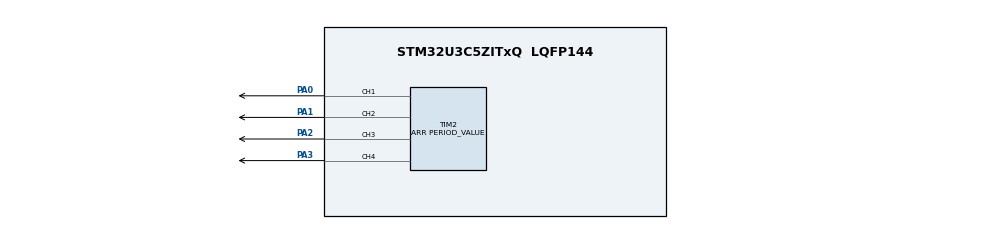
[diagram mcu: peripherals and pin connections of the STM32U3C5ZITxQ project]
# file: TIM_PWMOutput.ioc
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CORTEX_M33_NS.userName=CORTEX_M33
Mcu.Family=STM32U3
Mcu.Name=STM32U3C5ZITxQ
Mcu.Package=LQFP144
NVIC.PriorityGroup=NVIC_PRIORITYGROUP_4
PA0.GPIO_PuPd=GPIO_PULLUP
PA0.GPIO_Speed=GPIO_SPEED_FREQ_VERY_HIGH
PA0.Signal=S_TIM2_CH1
PA1.GPIO_PuPd=GPIO_PULLUP
PA1.GPIO_Speed=GPIO_SPEED_FREQ_VERY_HIGH
PA1.Signal=S_TIM2_CH2
PA2.GPIO_PuPd=GPIO_PULLUP
PA2.GPIO_Speed=GPIO_SPEED_FREQ_VERY_HIGH
PA2.Signal=S_TIM2_CH3
PA3.GPIO_PuPd=GPIO_PULLUP
PA3.GPIO_Speed=GPIO_SPEED_FREQ_VERY_HIGH
PA3.Signal=S_TIM2_CH4
ProjectManager.HeapSize=0x200
ProjectManager.StackSize=0x400
ProjectManager.TargetToolchain=EWARM V9.20
RCC.ADCFreq_Value=96000000
RCC.AHBFreq_Value=96000000
RCC.APB1Freq_Value=96000000
RCC.APB1TimFreq_Value=96000000
RCC.APB2Freq_Value=96000000
RCC.APB2TimFreq_Value=96000000
RCC.APB3Freq_Value=96000000
RCC.CortexFreq_Value=12000000
RCC.HCLKFreq_Value=96000000
RCC.HSE_VALUE=16000000
RCC.HSI48_VALUE=48000000
RCC.HSI_VALUE=16000000
RCC.LSE_VALUE=32768
RCC.LSIDIV_VALUE=32000
RCC.MSISDIV=RCC_MSI_DIV1
RCC.MSI_VALUE=96000000
RCC.PWR_Regulator_Voltage_Scale=PWR_REGULATOR_VOLTAGE_SCALE1
RCC.SYSCLKFreq_VALUE=96000000
RCC.USBFreq_Value=96000000
SH.S_TIM2_CH1.0=TIM2_CH1,PWM Generation1 CH1
SH.S_TIM2_CH2.0=TIM2_CH2,PWM Generation2 CH2
SH.S_TIM2_CH3.0=TIM2_CH3,PWM Generation3 CH3
SH.S_TIM2_CH4.0=TIM2_CH4,PWM Generation4 CH4
TIM2.AutoReloadPreload=TIM_AUTORELOAD_PRELOAD_DISABLE
TIM2.Channel-PWM\ Generation1\ CH1=TIM_CHANNEL_1
TIM2.Channel-PWM\ Generation2\ CH2=TIM_CHANNEL_2
TIM2.Channel-PWM\ Generation3\ CH3=TIM_CHANNEL_3
TIM2.Channel-PWM\ Generation4\ CH4=TIM_CHANNEL_4
TIM2.ClearInputSource=TIM_CLEARINPUTSOURCE_NONE
TIM2.ClockDivision=TIM_CLOCKDIVISION_DIV1
TIM2.CounterMode=TIM_COUNTERMODE_UP
TIM2.OC1Preload_PWM=ENABLE
TIM2.OC2Preload_PWM=ENABLE
TIM2.OC3Preload_PWM=ENABLE
TIM2.OC4Preload_PWM=ENABLE
TIM2.OCFastMode_PWM-PWM\ Generation1\ CH1=TIM_OCFAST_DISABLE
TIM2.OCFastMode_PWM-PWM\ Generation2\ CH2=TIM_OCFAST_DISABLE
TIM2.OCFastMode_PWM-PWM\ Generation3\ CH3=TIM_OCFAST_DISABLE
TIM2.OCFastMode_PWM-PWM\ Generation4\ CH4=TIM_OCFAST_DISABLE
TIM2.OCMode_PWM-PWM\ Generation1\ CH1=TIM_OCMODE_PWM1
TIM2.OCMode_PWM-PWM\ Generation2\ CH2=TIM_OCMODE_PWM1
TIM2.OCMode_PWM-PWM\ Generation3\ CH3=TIM_OCMODE_PWM1
TIM2.OCMode_PWM-PWM\ Generation4\ CH4=TIM_OCMODE_PWM1
TIM2.OCPolarity_1=TIM_OCPOLARITY_HIGH
TIM2.OCPolarity_2=TIM_OCPOLARITY_HIGH
TIM2.OCPolarity_3=TIM_OCPOLARITY_HIGH
TIM2.OCPolarity_4=TIM_OCPOLARITY_HIGH
TIM2.Period=PERIOD_VALUE
TIM2.Prescaler=PRESCALER_VALUE
TIM2.PulseNoDither_1=PULSE1_VALUE
TIM2.PulseNoDither_2=PULSE2_VALUE
TIM2.PulseNoDither_3=PULSE3_VALUE
TIM2.PulseNoDither_4=PULSE4_VALUE
TIM2.TIM_MasterOutputTrigger=TIM_TRGO_RESET
TIM2.TIM_MasterSlaveMode=TIM_MASTERSLAVEMODE_DISABLE
VP_ICACHE_VS_ICACHE.Mode=DirectMappedCache
VP_PWR_VS_DBSignals.Mode=DisableDeadBatterySignals
VP_PWR_VS_LPOM.Mode=PowerOptimisation
VP_PWR_VS_SECSignals.Mode=Security/Privilege
board=custom

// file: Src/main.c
/* USER CODE BEGIN Header */
/**
  ******************************************************************************
  * @file    TIM/TIM_PWMOutput/Src/main.c
  * @author  MCD Application Team
  * @brief   This sample code shows how to use STM32U3xx TIM HAL API to generate
  *          4 signals in PWM.
  ******************************************************************************
  * @attention
  *
  * Copyright (c) 2025 STMicroelectronics.
  * All rights reserved.
  *
  * This software is licensed under terms that can be found in the LICENSE file
  * in the root directory of this software component.
  * If no LICENSE file comes with this software, it is provided AS-IS.
  *
  ******************************************************************************
  */
/* USER CODE END Header */
#include "main.h"

TIM_HandleTypeDef htim2;

void SystemClock_Config(void);
static void MX_GPIO_Init(void);
static void MX_TIM2_Init(void);
static void MX_ICACHE_Init(void);

int main(void)
{

  /* USER CODE BEGIN 1 */

  /* STM32U3xx HAL library initialization:
       - Configure the Flash prefetch
       - Configure the Systick to generate an interrupt each 1 msec
       - Set NVIC Group Priority to 4
       - Low Level Initialization
     */
  /* USER CODE END 1 */

  /* MCU Configuration--------------------------------------------------------*/

  /* Reset of all peripherals, Initializes the Flash interface and the Systick. */
  HAL_Init();

  /* Configure the system clock */
  SystemClock_Config();

  /* USER CODE BEGIN SysInit */

  /* Configure LD2 */
  BSP_LED_Init(LD2);

  /* USER CODE END SysInit */

  /* Initialize all configured peripherals */
  MX_GPIO_Init();
  MX_TIM2_Init();
  MX_ICACHE_Init();
  /* USER CODE BEGIN 2 */

/*## Start PWM signals generation #######################################*/
  /* Start channel 1 */
  if (HAL_TIM_PWM_Start(&htim2, TIM_CHANNEL_1) != HAL_OK)
  {
    /* PWM Generation Error */
    Error_Handler();
  }
  /* Start channel 2 */
  if (HAL_TIM_PWM_Start(&htim2, TIM_CHANNEL_2) != HAL_OK)
  {
    /* PWM Generation Error */
    Error_Handler();
  }
  /* Start channel 3 */
  if (HAL_TIM_PWM_Start(&htim2, TIM_CHANNEL_3) != HAL_OK)
  {
    /* PWM generation Error */
    Error_Handler();
  }
  /* Start channel 4 */
  if (HAL_TIM_PWM_Start(&htim2, TIM_CHANNEL_4) != HAL_OK)
  {
    /* PWM generation Error */
    Error_Handler();
  }

  /* USER CODE END 2 */

  /* Infinite loop */
  while (1)
  {

  }
}

void SystemClock_Config(void)
{
  RCC_OscInitTypeDef RCC_OscInitStruct = {0};
  RCC_ClkInitTypeDef RCC_ClkInitStruct = {0};

  /** Configure the System Power Supply
  */
  if (HAL_PWREx_ConfigSupply(PWR_SMPS_SUPPLY) != HAL_OK)
  {
    Error_Handler();
  }

  /** Enable Epod Booster
  */
  if (HAL_RCCEx_EpodBoosterClkConfig(RCC_EPODBOOSTER_SOURCE_MSIS, RCC_EPODBOOSTER_DIV1) != HAL_OK)
  {
    Error_Handler();
  }
  if (HAL_PWREx_EnableEpodBooster() != HAL_OK)
  {
    Error_Handler();
  }

  /** Configure the main internal regulator output voltage
  */
  if (HAL_PWREx_ControlVoltageScaling(PWR_REGULATOR_VOLTAGE_SCALE1) != HAL_OK)
  {
    Error_Handler();
  }

  /** Set Flash latency before increasing MSIS
  */
  __HAL_FLASH_SET_LATENCY(FLASH_LATENCY_3);

  /** Initializes the CPU, AHB and APB buses clocks
  */
  RCC_OscInitStruct.OscillatorType = RCC_OSCILLATORTYPE_MSIS;
  RCC_OscInitStruct.MSISState = RCC_MSI_ON;
  RCC_OscInitStruct.MSISSource = RCC_MSI_RC0;
  RCC_OscInitStruct.MSISDiv = RCC_MSI_DIV1;
  if (HAL_RCC_OscConfig(&RCC_OscInitStruct) != HAL_OK)
  {
    Error_Handler();
  }

  /** Initializes the CPU, AHB and APB buses clocks
  */
  RCC_ClkInitStruct.ClockType = RCC_CLOCKTYPE_HCLK|RCC_CLOCKTYPE_SYSCLK
                              |RCC_CLOCKTYPE_PCLK1|RCC_CLOCKTYPE_PCLK2
                              |RCC_CLOCKTYPE_PCLK3;
  RCC_ClkInitStruct.SYSCLKSource = RCC_SYSCLKSOURCE_MSIS;
  RCC_ClkInitStruct.AHBCLKDivider = RCC_SYSCLK_DIV1;
  RCC_ClkInitStruct.APB1CLKDivider = RCC_HCLK_DIV1;
  RCC_ClkInitStruct.APB2CLKDivider = RCC_HCLK_DIV1;
  RCC_ClkInitStruct.APB3CLKDivider = RCC_HCLK_DIV1;

  if (HAL_RCC_ClockConfig(&RCC_ClkInitStruct, FLASH_LATENCY_3) != HAL_OK)
  {
    Error_Handler();
  }
}

static void MX_ICACHE_Init(void)
{

  /** Enable instruction cache in 1-way (direct mapped cache)
  */
  if (HAL_ICACHE_ConfigAssociativityMode(ICACHE_1WAY) != HAL_OK)
  {
    Error_Handler();
  }
  if (HAL_ICACHE_Enable() != HAL_OK)
  {
    Error_Handler();
  }

}

static void MX_TIM2_Init(void)
{

  TIM_MasterConfigTypeDef sMasterConfig = {0};
  TIM_OC_InitTypeDef sConfigOC = {0};

  htim2.Instance = TIM2;
  htim2.Init.Prescaler = PRESCALER_VALUE;
  htim2.Init.CounterMode = TIM_COUNTERMODE_UP;
  htim2.Init.Period = PERIOD_VALUE;
  htim2.Init.ClockDivision = TIM_CLOCKDIVISION_DIV1;
  htim2.Init.AutoReloadPreload = TIM_AUTORELOAD_PRELOAD_DISABLE;
  if (HAL_TIM_PWM_Init(&htim2) != HAL_OK)
  {
    Error_Handler();
  }
  sMasterConfig.MasterOutputTrigger = TIM_TRGO_RESET;
  sMasterConfig.MasterSlaveMode = TIM_MASTERSLAVEMODE_DISABLE;
  if (HAL_TIMEx_MasterConfigSynchronization(&htim2, &sMasterConfig) != HAL_OK)
  {
    Error_Handler();
  }
  sConfigOC.OCMode = TIM_OCMODE_PWM1;
  sConfigOC.Pulse = PULSE1_VALUE;
  sConfigOC.OCPolarity = TIM_OCPOLARITY_HIGH;
  sConfigOC.OCFastMode = TIM_OCFAST_DISABLE;
  if (HAL_TIM_PWM_ConfigChannel(&htim2, &sConfigOC, TIM_CHANNEL_1) != HAL_OK)
  {
    Error_Handler();
  }
  sConfigOC.Pulse = PULSE2_VALUE;
  if (HAL_TIM_PWM_ConfigChannel(&htim2, &sConfigOC, TIM_CHANNEL_2) != HAL_OK)
  {
    Error_Handler();
  }
  sConfigOC.Pulse = PULSE3_VALUE;
  if (HAL_TIM_PWM_ConfigChannel(&htim2, &sConfigOC, TIM_CHANNEL_3) != HAL_OK)
  {
    Error_Handler();
  }
  sConfigOC.Pulse = PULSE4_VALUE;
  if (HAL_TIM_PWM_ConfigChannel(&htim2, &sConfigOC, TIM_CHANNEL_4) != HAL_OK)
  {
    Error_Handler();
  }
  HAL_TIM_MspPostInit(&htim2);

}

static void MX_GPIO_Init(void)
{

  /* GPIO Ports Clock Enable */
  __HAL_RCC_GPIOA_CLK_ENABLE();

}

void Error_Handler(void)
{
  /* USER CODE BEGIN Error_Handler_Debug */
  /* Turn LD2 on */
  BSP_LED_On(LD2);
  while(1)
  {
  }
  /* USER CODE END Error_Handler_Debug */
}
